VERSION ""

NS_ :

BS_:

BU_:
VAL_TABLE_ vt_BNRaccuracy 1 "DegradedAccuracy" 0 "NominalAccuracy" ;
VAL_TABLE_ vt_BCDstatus_above_below 3 "Below" 2 "FT" 1 "NCD" 0 "Above" ;
VAL_TABLE_ vt_BCDstatus_to_from 3 "From" 2 "FT" 1 "NCD" 0 "To" ;
VAL_TABLE_ vt_BCDstatus_right_left 3 "Left" 2 "FT" 1 "NCD" 0 "Right" ;
VAL_TABLE_ vt_BCDstatus_east_west 3 "West" 2 "FT" 1 "NCD" 0 "East" ;
VAL_TABLE_ vt_BCDstatus_north_south 3 "South" 2 "FT" 1 "NCD" 0 "North" ;
VAL_TABLE_ vt_BCDstatus_plus_minus 3 "Minus" 2 "FT" 1 "NCD" 0 "Plus" ;
VAL_TABLE_ vt_DSCstatus 3 "FW" 2 "FT" 1 "NCD" 0 "NO" ;
VAL_TABLE_ vt_BNRsign_above_below 1 "Below" 0 "Above" ;
VAL_TABLE_ vt_BNRsign_to_from 1 "From" 0 "To" ;
VAL_TABLE_ vt_BNRsign_right_left 1 "Left" 0 "Right" ;
VAL_TABLE_ vt_BNRsign_east_west 1 "West" 0 "East" ;
VAL_TABLE_ vt_BNRsign_north_south 1 "South" 0 "North" ;
VAL_TABLE_ vt_BNRsign_plus_minus 1 "Minus" 0 "Plus" ;
VAL_TABLE_ vt_BNRstatus 3 "NO" 2 "FT" 1 "NCD" 0 "FW" ;

BO_ 6 Master_State: 4 Vector__XXX
 SG_ Line_State : 31|2@1+ (1,0) [0|3] "" Vector__XXX
 SG_ Servo_Angle : 24|8@1+ (1,0) [0|180] "" Vector__XXX
 SG_ UltraSonic_Dist : 16|16@1+ (1,0) [0|65535] "" Vector__XXX
 SG_ Mode : 8|1@1+ (1,0) [0|1] "" Vector__XXX
 SG_ Avoid_Dir : 0|2@1- (1,0) [-128|127] "" Vector__XXX

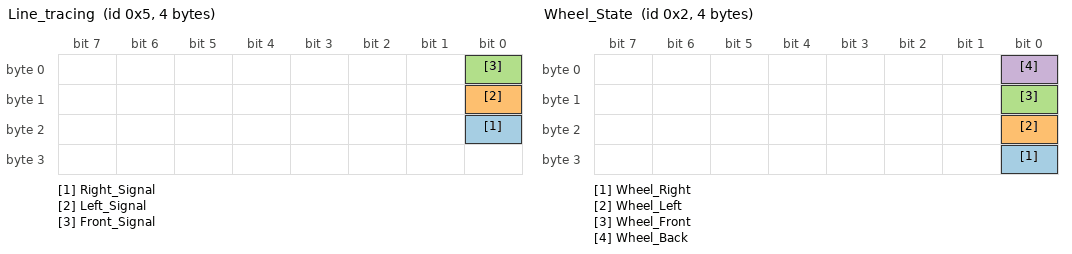
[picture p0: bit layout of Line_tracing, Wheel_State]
BO_ 5 Line_tracing: 4 Vector__XXX
 SG_ Right_Signal : 16|1@1+ (1,0) [0|1] "" Vector__XXX
 SG_ Left_Signal : 8|1@1+ (1,0) [-128|1] "" Vector__XXX
 SG_ Front_Signal : 0|1@1+ (1,0) [0|1] "" Vector__XXX

BO_ 4 Dynamic_Planning: 4 Vector__XXX
 SG_ Back_Signal : 24|1@1+ (1,0) [0|1] "" Vector__XXX
 SG_ Stop_Signal : 16|1@1+ (1,0) [0|1] "" Vector__XXX
 SG_ Servo_Angle : 8|8@1+ (1,0) [0|180] "" Vector__XXX
 SG_ Ultra_Sonic : 0|16@1+ (1,0) [0|255] "" Vector__XXX

BO_ 2 Wheel_State: 4 Vector__XXX
 SG_ Wheel_Right : 24|1@1+ (1,0) [0|1] "" Vector__XXX
 SG_ Wheel_Left : 16|1@1+ (1,0) [0|1] "" Vector__XXX
 SG_ Wheel_Front : 8|1@1+ (1,0) [0|1] "" Vector__XXX
 SG_ Wheel_Back : 0|1@1+ (1,0) [0|1] "" Vector__XXX

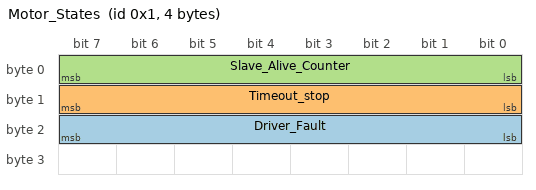
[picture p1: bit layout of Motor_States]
BO_ 1 Motor_States: 4 Vector__XXX
 SG_ Driver_Fault : 16|8@1+ (1,0) [0|1] "" Vector__XXX
 SG_ Timeout_stop : 8|8@1+ (1,0) [0|1] "" Vector__XXX
 SG_ Slave_Alive_Counter : 0|8@1+ (1,0) [0|255] "" Vector__XXX

BO_ 3 Motor_Cmd: 4 Vector__XXX
 SG_ EStop : 31|1@1+ (1,0) [0|1] "" Vector__XXX
 SG_ Motor_Enable : 31|1@1+ (1,0) [0|1] "" Vector__XXX
 SG_ Right_Motor_Dir : 24|1@1+ (1,0) [0|1] "" Vector__XXX
 SG_ Right_Motor_Pwm : 16|8@1+ (1,0) [0|255] "" Vector__XXX
 SG_ Left_Motor_Pwm : 8|8@1+ (1,0) [0|255] "" Vector__XXX
 SG_ Left_Motor_Dir : 0|1@1+ (1,0) [0|1] "" Vector__XXX

BA_DEF_ SG_  "GenSigStartValue" FLOAT 0 0;
BA_DEF_ BO_  "A429ExtendedID" ENUM  "Standard","Extended";
BA_DEF_  "TemplateVersion" STRING ;
BA_DEF_  "ProtocolType" STRING ;
BA_DEF_ BO_  "A429SpecSource" ENUM  "ARINC","GAMA","Private";
BA_DEF_ BO_  "A429Protocol" ENUM  "BC","AIM","A619","WB1","WB2","WB3";
BA_DEF_  "A429Parity" ENUM  "unknown","odd","even";
BA_DEF_ BU_  "A429Equipment" STRING ;
BA_DEF_  "Baudrate" INT 10500 110000;
BA_DEF_  "ToolName" STRING ;
BA_DEF_  "ToolVersion" STRING ;
BA_DEF_  "Manufacturer" STRING ;
BA_DEF_  "VersionDay" INT 0 31;
BA_DEF_  "VersionMonth" INT 0 12;
BA_DEF_  "VersionWeek" INT 0 0;
BA_DEF_  "BusType" STRING ;
BA_DEF_DEF_  "GenSigStartValue" 0;
BA_DEF_DEF_  "A429ExtendedID" "Standard";
BA_DEF_DEF_  "TemplateVersion" "1.1.0.0";
BA_DEF_DEF_  "ProtocolType" "Aerospace";
BA_DEF_DEF_  "A429SpecSource" "ARINC";
BA_DEF_DEF_  "A429Protocol" "BC";
BA_DEF_DEF_  "A429Parity" "odd";
BA_DEF_DEF_  "A429Equipment" "<unknown>";
BA_DEF_DEF_  "Baudrate" 100000;
BA_DEF_DEF_  "ToolName" "manually";
BA_DEF_DEF_  "ToolVersion" "x.y.z.n";
BA_DEF_DEF_  "Manufacturer" "<unknown>";
BA_DEF_DEF_  "VersionDay" 1;
BA_DEF_DEF_  "VersionMonth" 1;
BA_DEF_DEF_  "VersionWeek" 1;
BA_DEF_DEF_  "BusType" "ARINC429";
BA_ "GenSigStartValue" SG_ 6 Servo_Angle 90;
BA_ "GenSigStartValue" SG_ 3 Motor_Enable 1;
